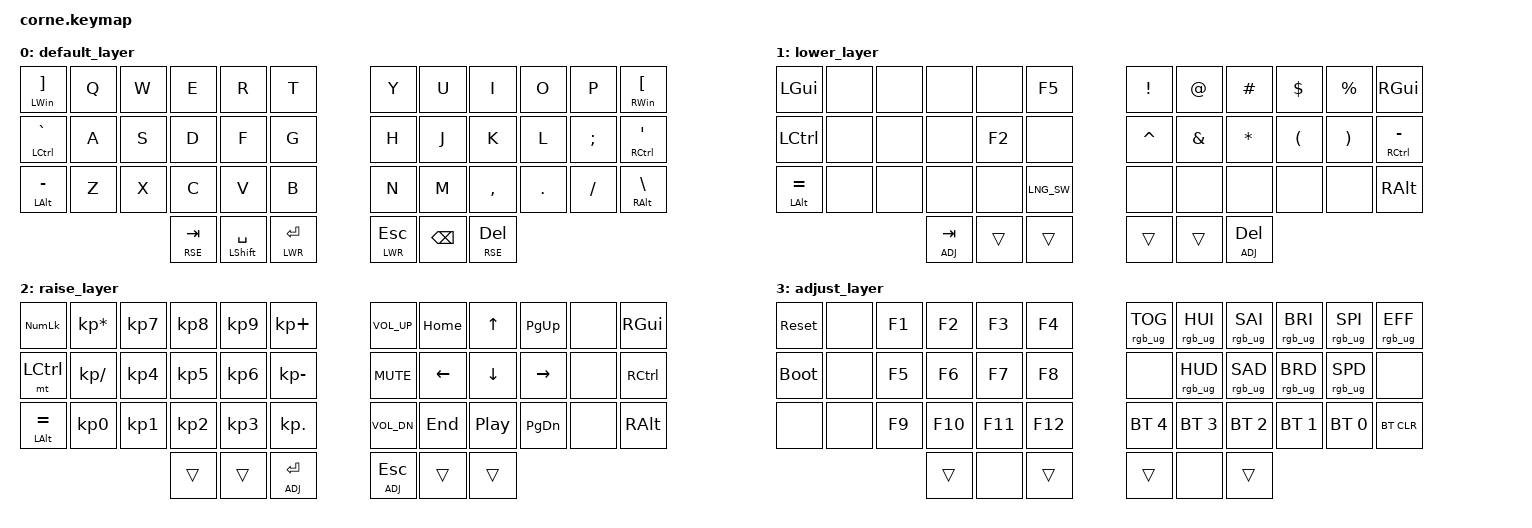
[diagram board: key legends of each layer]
/*
 * Copyright (c) 2020 The ZMK Contributors
 *
 * SPDX-License-Identifier: MIT
 */

#include <behaviors.dtsi>
#include <dt-bindings/zmk/keys.h>
#include <dt-bindings/zmk/bt.h>
#include <dt-bindings/zmk/rgb.h>
// #include <dt-bindings/zmk/rgb.h>

#define DEF 0
#define LWR 1
#define RSE 2
#define ADJ 3

/ {
    macros {
       LNG_SW: LNG_SW {
            label = "ZM_LNG_SW";
            compatible = "zmk,behavior-macro";
            #binding-cells = <0>;
            bindings
                = <&macro_press &kp LGUI>
                , <&macro_tap &kp SPACE>
                , <&macro_release &kp LGUI>
                ;
        };
    };

    behaviors {
        sm: space_mod {
            compatible = "zmk,behavior-hold-tap";
            label = "SPACE_MOD";
            #binding-cells = <2>;
            flavor = "balanced";
            tapping-term-ms = <200>;
            quick-tap-ms = <125>;
            bindings = <&kp>, <&kp>;
        };
    };
};

&led_strip {
    chain-length = <30>;
};


/ {
        keymap {
                compatible = "zmk,keymap";

                default_layer {
// -----------------------------------------------------------------------------------------
//        | GUY/]  |  Q  |  W  |  E  |  R  |  T  |   |  Y  |  U   |  I  |  O  |  P  | GUI/[ |
//        | CTRL/` |  A  |  S  |  D  |  F  |  G  |   |  H  |  J   |  K  |  L  |  ;  |CTRL/'|
//        | LALT/- |  Z  |  X  |  C  |  V  |  B  |   |  N  |  M   |  ,  |  .  |  /  | RALT \ |
//                           | RSE | SPC | LWR |   | LWR | BKSP | RSE |
                        bindings = <
            &mt LWIN RBKT   &kp Q &kp W &kp E &kp R &kp T               &kp Y  &kp U  &kp I     &kp O   &kp P     &mt RWIN LBKT
            &mt LCTRL GRAVE &kp A &kp S &kp D &kp F &kp G               &kp H  &kp J  &kp K     &kp L   &kp SEMI  &mt RCTRL SQT
            &mt LALT MINUS  &kp Z &kp X &kp C &kp V &kp B               &kp N  &kp M  &kp COMMA &kp DOT &kp FSLH  &mt RALT BSLH
                  &lt RSE TAB &sm LSHFT SPACE &lt LWR RET               &lt LWR ESC &kp BSPC &lt RSE DEL
                        >;
                };
          
                lower_layer {
// -----------------------------------------------------------------------------------------
// |     |     |     |     |     |     |  F5 |        |  !  |  @  |  #   |  $ |  %   | GUI |
//       |   CTRL  |     |     |     |     |    |        |  ^  |  &  |  *  |  (  |  )  |  CTRL/- |
//       |  =  |     |     |     |     |  LNG SW  |        |     |     |     |     |     |   ALT  |
//                         | TAB |     |     |        |     |     | DEL |
                        bindings = <
          &kp LGUI       &none   &none &none  &none   &kp F5                   &kp EXCL  &kp AT   &kp HASH &kp DOLLAR  &kp PERCENT  &kp RGUI
          &kp LCTRL      &none   &none &none  &kp F2  &none                    &kp CARET &kp AMPS &kp STAR &kp LPAR    &kp RPAR     &mt RCTRL MINUS
          &mt LALT EQUAL &none   &none &none  &none   &LNG_SW                  &none     &none    &none    &none       &none        &kp RALT
                                              &lt ADJ TAB &trans &trans        &trans &trans &lt ADJ DEL
                        >;
                };

                raise_layer {
// -----------------------------------------------------------------------------------------
// |     | NMLK |  *  |  7  |  8  |  9  |  +  |   | VOLU| HOME| PRSC| PGUP| SCLK| CLCK|     |
//       | CTRL |  /  |  4  |  5  |  6  | -  |   | MUT | LEFT|  UP | RGHT| INS | APP |
//       | LATL/=|  0  |  1  |  2  |  3  |  .  |   | VOLD| END | DOWN| PGDN| PAUS|     |
//                          |     |     | ADJ |   | ADJ |     |     |
                        bindings = <
          &kp KP_NUM            &kp KP_MULTIPLY &kp KP_N7 &kp KP_N8 &kp KP_N9 &kp KP_PLUS               &kp C_VOL_UP &kp HOME &kp UP            &kp PG_UP &none &kp RGUI
          &mt LCTRL             &kp KP_SLASH    &kp KP_N4 &kp KP_N5 &kp KP_N6 &kp KP_MINUS              &kp C_MUTE   &kp LEFT &kp DOWN          &kp RIGHT &none &kp RCTRL
          &mt LEFT_ALT EQUAL    &kp KP_N0       &kp KP_N1 &kp KP_N2 &kp KP_N3 &kp KP_DOT                &kp C_VOL_DN &kp END  &kp C_PLAY_PAUSE  &kp PG_DN &none &kp RALT
                                                           &trans &trans &lt ADJ RET   &lt ADJ ESC &trans &trans
                        >;
                };

                adjust_layer {
// -----------------------------------------------------------------------------------------
// | RST | BLDR |     |     |     |     |     |   |     |     |     |     |     | BLDR | RST |
//       | BTCLR| BT0 | BT1 | BT2 | BT3 | BT4 |   | BT4 | BT3 | BT2 | BT1 | BT0 | BTCLR|
//       |      |     |     |     |     |     |   |     |     |     |     |     |      |
//                          |     |     |     |   |     |     |     |
                        bindings = <
          &sys_reset        &none &kp F1 &kp F2  &kp F3  &kp F4                       &rgb_ug  RGB_TOG &rgb_ug  RGB_HUI  &rgb_ug  RGB_SAI  &rgb_ug  RGB_BRI &rgb_ug  RGB_SPI &rgb_ug  RGB_EFF
          &bootloader   &none &kp F5 &kp F6  &kp F7  &kp F8                       &none            &rgb_ug  RGB_HUD  &rgb_ug  RGB_SAD  &rgb_ug  RGB_BRD &rgb_ug  RGB_SPD &none
          &none         &none &kp F9 &kp F10 &kp F11 &kp F12                      &bt BT_SEL 4     &bt BT_SEL 3      &bt BT_SEL 2      &bt BT_SEL 1     &bt BT_SEL 0     &bt BT_CLR  
                                        &trans &none &trans   &trans &none &trans
                        >;
                };
        };
};




